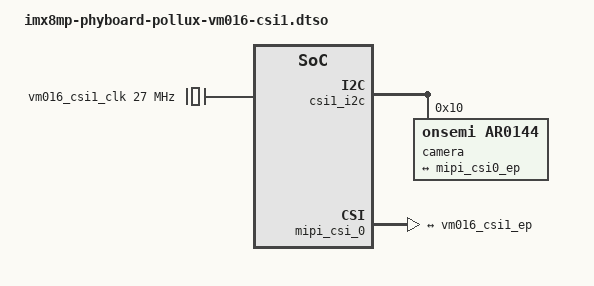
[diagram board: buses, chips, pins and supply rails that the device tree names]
// SPDX-License-Identifier: (GPL-2.0+ OR MIT)
/*
 * Copyright (C) 2022 PHYTEC Messtechnik GmbH
 * Author: Stefan Riedmueller <s.riedmueller@phytec.de>
 */

/dts-v1/;
/plugin/;

&{/} {
	vm016_csi1_clk: vm016-csi1-ext-clk {
		#clock-cells = <0>;
		compatible = "fixed-clock";
		clock-frequency = <27000000>;
	};
};

&csi1_i2c {
	#address-cells = <1>;
	#size-cells = <0>;

	camera@10 {
		#address-cells = <0x1>;
		#size-cells = <0x0>;

		compatible = "onsemi,ar0144";
		reg = <0x10>;
		clocks = <&vm016_csi1_clk>;
		clock-names = "ext";
		isp-bus-info = "csi0";

		port@0 {
			reg = <0>;

			vm016_csi1_ep: endpoint {
				remote-endpoint = <&mipi_csi0_ep>;
				bus-type = <4>; /* MIPI CSI-2 D-PHY */
				link-frequencies = /bits/ 64 <222750000>;
				data-lanes = <1 2>;
				clock-lanes = <0>;
				clock-noncontinuous = <1>;
				onsemi,t-hs-prep = <1>;
				onsemi,t-clk-post = <9>;
			};
		};
	};
};

&mipi_csi_0 {
	#address-cells = <1>;
	#size-cells = <0>;

	port@0 {
		reg = <0>;
		mipi_csi0_ep: endpoint {
			remote-endpoint = <&vm016_csi1_ep>;
			data-lanes = <2>;
			csis-hs-settle = <13>;
			csis-clk-settle = <2>;
			csis-wclk;
		};
	};
};
